# ATtiny1607 register map
Vendor: Atmel; File version: 1.0
CPU: other r0p0, little endian, no MPU, no FPU, 4 interrupt priority bits
Registers are 8-bit, read-write, reset 0x0 unless marked. A register's access mark holds for its fields unless they carry their own. Offsets are from the block's base; [hi:lo] are bit positions; {n}, {i} and the like mark numbered series.

## PORTA — I/O Ports
Base 0x00800400
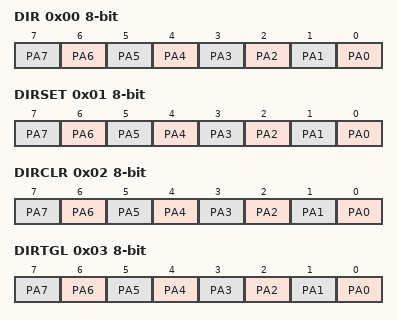
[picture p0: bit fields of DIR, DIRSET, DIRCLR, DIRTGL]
0x00 DIR — Data Direction
  [n] PA{n} (n=0..7) — Pin A{n}
0x01 DIRSET — Data Direction Set
  [n] PA{n} (n=0..7) — Pin A{n}
0x02 DIRCLR — Data Direction Clear
  [n] PA{n} (n=0..7) — Pin A{n}
0x03 DIRTGL — Data Direction Toggle
  [n] PA{n} (n=0..7) — Pin A{n}
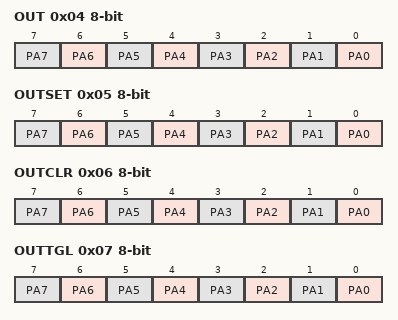
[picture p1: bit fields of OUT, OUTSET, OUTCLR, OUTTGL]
0x04 OUT — Output Value
  [n] PA{n} (n=0..7) — Pin A{n}
0x05 OUTSET — Output Value Set
  [n] PA{n} (n=0..7) — Pin A{n}
0x06 OUTCLR — Output Value Clear
  [n] PA{n} (n=0..7) — Pin A{n}
0x07 OUTTGL — Output Value Toggle
  [n] PA{n} (n=0..7) — Pin A{n}
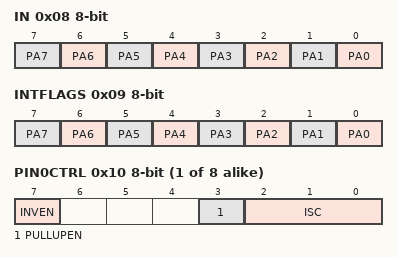
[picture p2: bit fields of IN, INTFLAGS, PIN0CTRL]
0x08 IN — Input Value
  [n] PA{n} (n=0..7) — Pin A{n}
0x09 INTFLAGS — Interrupt Flags
  [n] PA{n} (n=0..7) — Pin A{n}
{0x10+i} PIN{i}CTRL (i=0..7) — Pin {i} Control
  [7] INVEN — Inverted I/O Enable
  [3] PULLUPEN — Pullup enable
  [2:0] ISC — Input/Sense Configuration
    0=INTDISABLE (Interrupt disabled but input buffer enabled); 1=BOTHEDGES (Sense Both Edges); 2=RISING (Sense Rising Edge); 3=FALLING (Sense Falling Edge); 4=INPUT_DISABLE (Digital Input Buffer disabled); 5=LEVEL (Sense low Level)

## PORTB — I/O Ports
Base 0x00800420
Registers as PORTA; these are added or differ:
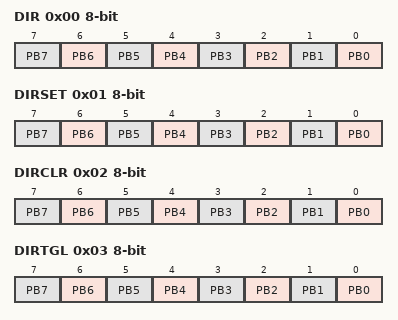
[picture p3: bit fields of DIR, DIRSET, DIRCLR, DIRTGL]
0x00 DIR — Data Direction
  [n] PB{n} (n=0..7) — Pin B{n}
0x01 DIRSET — Data Direction Set
  [n] PB{n} (n=0..7) — Pin B{n}
0x02 DIRCLR — Data Direction Clear
  [n] PB{n} (n=0..7) — Pin B{n}
0x03 DIRTGL — Data Direction Toggle
  [n] PB{n} (n=0..7) — Pin B{n}
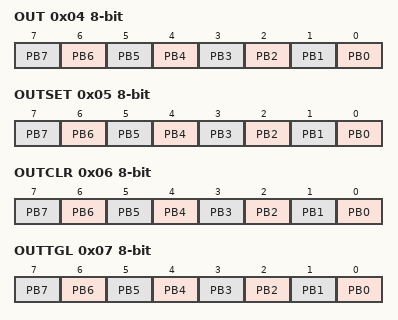
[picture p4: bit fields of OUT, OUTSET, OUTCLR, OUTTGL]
0x04 OUT — Output Value
  [n] PB{n} (n=0..7) — Pin B{n}
0x05 OUTSET — Output Value Set
  [n] PB{n} (n=0..7) — Pin B{n}
0x06 OUTCLR — Output Value Clear
  [n] PB{n} (n=0..7) — Pin B{n}
0x07 OUTTGL — Output Value Toggle
  [n] PB{n} (n=0..7) — Pin B{n}
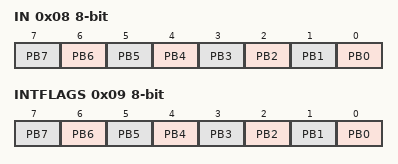
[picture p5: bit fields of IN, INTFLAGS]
0x08 IN — Input Value
  [n] PB{n} (n=0..7) — Pin B{n}
0x09 INTFLAGS — Interrupt Flags
  [n] PB{n} (n=0..7) — Pin B{n}

## PORTC — I/O Ports
Base 0x00800440
Registers as PORTA; these are added or differ:
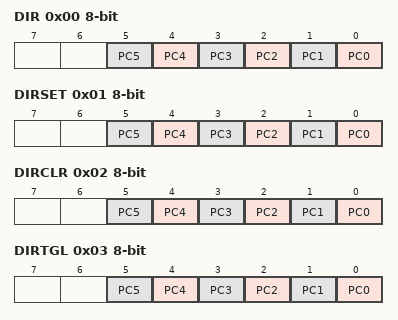
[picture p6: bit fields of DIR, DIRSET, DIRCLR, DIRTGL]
0x00 DIR — Data Direction
  [n] PC{n} (n=0..5) — Pin C{n}
0x01 DIRSET — Data Direction Set
  [n] PC{n} (n=0..5) — Pin C{n}
0x02 DIRCLR — Data Direction Clear
  [n] PC{n} (n=0..5) — Pin C{n}
0x03 DIRTGL — Data Direction Toggle
  [n] PC{n} (n=0..5) — Pin C{n}
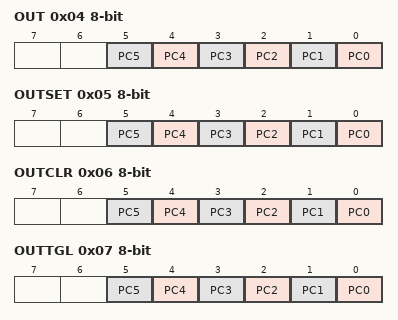
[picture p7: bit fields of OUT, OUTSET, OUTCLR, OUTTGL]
0x04 OUT — Output Value
  [n] PC{n} (n=0..5) — Pin C{n}
0x05 OUTSET — Output Value Set
  [n] PC{n} (n=0..5) — Pin C{n}
0x06 OUTCLR — Output Value Clear
  [n] PC{n} (n=0..5) — Pin C{n}
0x07 OUTTGL — Output Value Toggle
  [n] PC{n} (n=0..5) — Pin C{n}
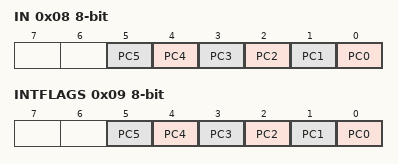
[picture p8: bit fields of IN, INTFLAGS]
0x08 IN — Input Value
  [n] PC{n} (n=0..5) — Pin C{n}
0x09 INTFLAGS — Interrupt Flags
  [n] PC{n} (n=0..5) — Pin C{n}

## PORTMUX — Port Multiplexer
Base 0x00800200
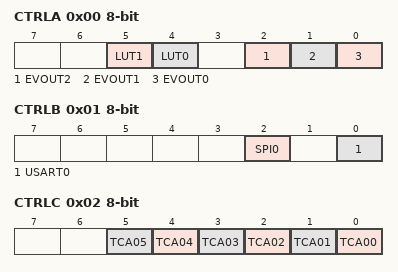
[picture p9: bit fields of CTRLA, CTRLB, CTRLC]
0x00 CTRLA — Port Multiplexer Control A
  [5] LUT1 — Configurable Custom Logic LUT1
    0=DEFAULT (Default pin); 1=ALTERNATE (Alternate pin)
  [4] LUT0 — Configurable Custom Logic LUT0
    0=DEFAULT (Default pin); 1=ALTERNATE (Alternate pin)
  [2] EVOUT2 — Event Output 2
  [1] EVOUT1 — Event Output 1
  [0] EVOUT0 — Event Output 0
0x01 CTRLB — Port Multiplexer Control B
  [2] SPI0 — Port Multiplexer SPI0
    0=DEFAULT (Default pins); 1=ALTERNATE (Alternate pins)
  [0] USART0 — Port Multiplexer USART0
    0=DEFAULT (Default pins); 1=ALTERNATE (Alternate pins)
0x02 CTRLC — Port Multiplexer Control C
  [all] fields
    0=DEFAULT (Default pin); 1=ALTERNATE (Alternate pin)
  [n] TCA{n:02} (n=0..5) — Port Multiplexer TCA0 Output {n}
0x03 CTRLD — Port Multiplexer Control D
  [0] TCB0 — Port Multiplexer TCB
    0=DEFAULT (Default pin); 1=ALTERNATE (Alternate pin)

## RSTCTRL — Reset controller
Base 0x00800040
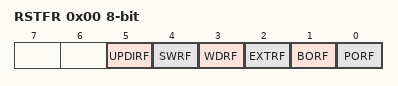
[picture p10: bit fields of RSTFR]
0x00 RSTFR — Reset Flags
  [5] UPDIRF — UPDI Reset flag
  [4] SWRF — Software Reset flag
  [3] WDRF — Watch dog Reset flag
  [2] EXTRF — External Reset flag
  [1] BORF — Brown out detector Reset flag
  [0] PORF — Power on Reset flag
0x01 SWRR — Software Reset
  [0] SWRE — Software reset enable
